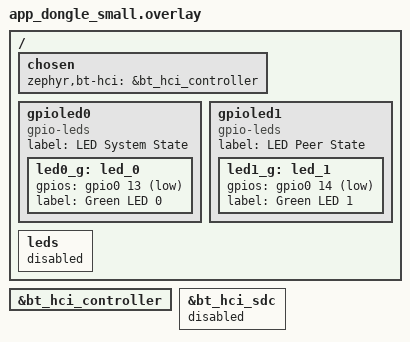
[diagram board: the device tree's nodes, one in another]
/*
 * Copyright (c) 2025-2026 Nordic Semiconductor ASA
 *
 * SPDX-License-Identifier: LicenseRef-Nordic-5-Clause
 */

#include "memory_map_dongle_small.dtsi"
#include "app_common.dtsi"

/ {
	chosen {
		zephyr,bt-hci = &bt_hci_controller;
	};

	gpioled0 {
		compatible = "gpio-leds";
		status = "okay";
		label = "LED System State";

		led0_g: led_0 {
			gpios = <&gpio0 13 GPIO_ACTIVE_LOW>;
			label = "Green LED 0";
		};
	};

	gpioled1 {
		compatible = "gpio-leds";
		status = "okay";
		label = "LED Peer State";

		led1_g: led_1 {
			gpios = <&gpio0 14 GPIO_ACTIVE_LOW>;
			label = "Green LED 1";
		};
	};

	leds {
		status = "disabled";
	};
};

&bt_hci_controller {
	status = "okay";
};

&bt_hci_sdc {
	status = "disabled";
};
